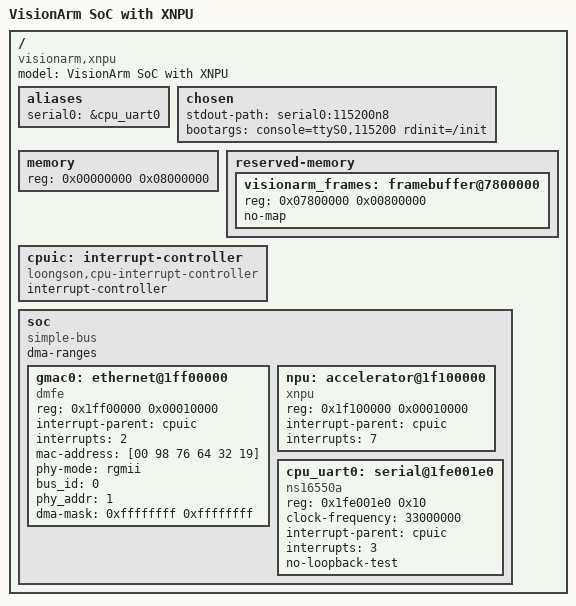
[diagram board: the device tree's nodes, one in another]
// SPDX-License-Identifier: GPL-2.0
/dts-v1/;

/ {
	model = "VisionArm SoC with XNPU";
	compatible = "visionarm,xnpu", "loongson,loongson3";
	#address-cells = <1>;
	#size-cells = <1>;

	aliases {
		serial0 = &cpu_uart0;
	};

	chosen {
		stdout-path = "serial0:115200n8";
		bootargs = "console=ttyS0,115200 rdinit=/init";
	};

	memory {
		device_type = "memory";
		reg = <0x00000000 0x08000000>;
	};

	reserved-memory {
		#address-cells = <1>;
		#size-cells = <1>;
		ranges;

		/*
		 * Keep Linux allocations out of the top 8 MiB while retaining the
		 * full physical DDR range for /dev/mem mappings used by the LCD and
		 * camera capture tools.  The fixed camera buffers are at 0x07c00000
		 * and 0x07d00000; the LCD staging frame starts at 0x07800000.
		 */
		visionarm_frames: framebuffer@7800000 {
			reg = <0x07800000 0x00800000>;
			no-map;
		};
	};

	cpuic: interrupt-controller {
		compatible = "loongson,cpu-interrupt-controller";
		interrupt-controller;
		#interrupt-cells = <1>;
	};

	soc {
		compatible = "simple-bus";
		#address-cells = <1>;
		#size-cells = <1>;
		ranges = <0x10000000 0x10000000 0x10000000>;
		dma-ranges;

		gmac0: ethernet@1ff00000 {
			compatible = "dmfe";
			reg = <0x1ff00000 0x00010000>;
			interrupt-parent = <&cpuic>;
			/* FPGA intrpt[0] maps to LoongArch CPU HWIRQ 2. */
			interrupts = <2>;
			interrupt-names = "macirq";
			mac-address = [00 98 76 64 32 19];
			phy-mode = "rgmii";
			bus_id = <0>;
			phy_addr = <1>;
			dma-mask = <0xffffffff 0xffffffff>;
		};

		npu: accelerator@1f100000 {
			compatible = "xnpu";
			reg = <0x1f100000 0x00010000>;
			interrupt-parent = <&cpuic>;
			/* FPGA intrpt[5] maps to LoongArch CPU HWIRQ 7. */
			interrupts = <7>;
		};

		cpu_uart0: serial@1fe001e0 {
			compatible = "ns16550a";
			reg = <0x1fe001e0 0x10>;
			clock-frequency = <33000000>;
			interrupt-parent = <&cpuic>;
			interrupts = <3>;
			no-loopback-test;
		};
	};
};
